# R7FA6M2AF register map
Vendor: Renesas; Series: RA6; File version: 1.2
CPU: CM4 r0p1, little endian, MPU, FPU, VTOR, 4 interrupt priority bits
Registers are 8-bit, read-write, reset 0x0 unless marked. A register's access mark holds for its fields unless they carry their own. Offsets are from the block's base; [hi:lo] are bit positions.

## ETHERC0 — Ethernet Controller Channel 0
Base 0x40064100
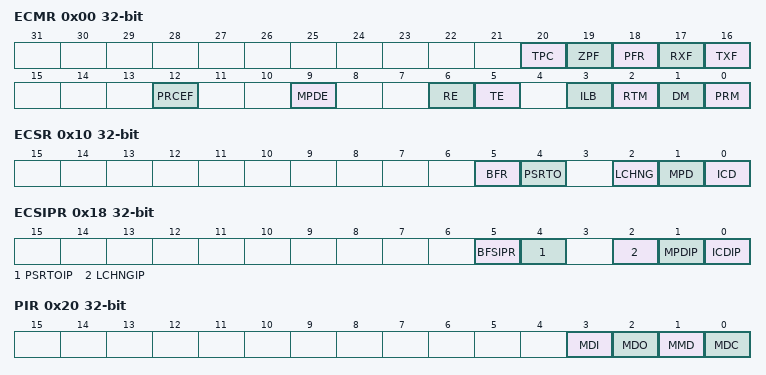
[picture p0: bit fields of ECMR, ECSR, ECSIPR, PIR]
0x00 ECMR 32-bit — ETHERC Mode Register
  [20] TPC — PAUSE Frame Transmit
  [19] ZPF — 0 Time PAUSE Frame Enable
  [18] PFR — PAUSE Frame Receive Mode
  [17] RXF — Receive Flow Control Operating Mode
  [16] TXF — Transmit Flow Control Operating Mode
  [12] PRCEF — CRC Error Frame Receive Mode
  [9] MPDE — Magic Packet Detection Enable
  [6] RE — Reception Enable
  [5] TE — Transmission Enable
  [3] ILB — Internal Loopback Mode
  [2] RTM — Bit Rate
  [1] DM — Duplex Mode
  [0] PRM — Promiscuous Mode
0x08 RFLR 32-bit — Receive Frame Maximum Length Register
  [11:0] RFL — Receive Frame Maximum LengthThe set value becomes the maximum frame length. The minimum value that can be set is 1,518 bytes, and the maximum value that can be set is 2,048 bytes. Values that are less than 1,518 bytes are regarded as 1,518 bytes, and values larger than 2,048 bytes are regarded as 2,048 bytes.
0x10 ECSR 32-bit — ETHERC Status Register
  [5] BFR write-1-clears read-modifies — Continuous Broadcast Frame Reception Flag
  [4] PSRTO write-1-clears read-modifies — PAUSE Frame Retransmit Over Flag
  [2] LCHNG write-1-clears read-modifies — LCHNG Link Signal Change Flag
  [1] MPD write-1-clears read-modifies — Magic Packet Detect Flag
  [0] ICD write-1-clears read-modifies — False Carrier Detect Flag
0x18 ECSIPR 32-bit — ETHERC Interrupt Enable Register
  [5] BFSIPR — Continuous Broadcast Frame Reception Interrupt Enable
  [4] PSRTOIP — PAUSE Frame Retransmit Over Interrupt Enable
  [2] LCHNGIP — LINK Signal Change Interrupt Enable
  [1] MPDIP — Magic Packet Detect Interrupt Enable
  [0] ICDIP — False Carrier Detect Interrupt Enable
0x20 PIR 32-bit (reset mask 0xFFFFFFF7) — PHY Interface Register
  [3] MDI ro — MII/RMII Management Data,InThis bit indicates the level of the ETn_MDIO pin. The write value should be 0.
  [2] MDO — MII/RMII Management Data,OutThe MDO bit value is output from the ETn_MDIO pin when the MMD bit is 1 (write). The value is not output when the MMD bit is 0 (read).
  [1] MMD — MII/RMII Management Mode
  [0] MDC — MII/RMII Management Data ClockThe MDC bit value is output from the ETn_MDC pin to supply the management data clock to the MII or RMII.
0x28 PSR 32-bit ro (reset mask 0xFFFFFFFE) — PHY Status Register
  [0] LMON — ETn_LINKSTA Pin Status FlagThe link status can be read by connecting the link signal output from the PHY,LSI to the ETn_LINKSTA pin. For details on the polarity, refer to the specifications of the connected PHY,LSI.
0x40 RDMLR 32-bit — Random Number Generation Counter Upper Limit Setting Register
  [19:0] RMD — Random Number Generation Counter
0x50 IPGR 32-bit reset 0x14 — IPG Register
  [4:0] IPG — Interpacket Gap Range:"16bit time(0x00)"-"140bit time(0x1F)"
0x54 APR 32-bit — Automatic PAUSE Frame Register
  [15:0] AP — Automatic PAUSE Time SettingThese bits set the value of the pause_time parameter for a PAUSE frame that is automatically transmitted. Transmission is not performed until the set value multiplied by 512 bit time has elapsed.
0x58 MPR 32-bit wo (reset mask 0xFFFF0000) — Manual PAUSE Frame Register
  [15:0] MP — Manual PAUSE Time SettingThese bits set the value of the pause_time parameter for a PAUSE frame that is manually transmitted. Transmission is not performed until the set value multiplied by 512 bit time has elapsed. The read value is undefined.
0x60 RFCF 32-bit ro — Received PAUSE Frame Counter
  [7:0] RPAUSE — Received PAUSE Frame CountNumber of received PAUSE frames
0x64 TPAUSER 32-bit — PAUSE Frame Retransmit Count Setting Register
  [15:0] TPAUSE — Automatic PAUSE Frame Retransmit Setting
0x68 TPAUSECR 32-bit ro — PAUSE Frame Retransmit Counter
0x6C BCFRR 32-bit — Broadcast Frame Receive Count Setting Register
  [15:0] BCF — Broadcast Frame Continuous Receive Count Setting
0xC0 MAHR 32-bit — MAC Address Upper Bit Register
  [31:0] MAHR — MAC Address Upper Bit RegisterThe MAHR register sets the upper 32 bits (b47 to b16) of the 48-bit MAC address.
0xC8 MALR 32-bit — MAC Address Lower Bit Register
  [15:0] MALR — MAC Address Lower Bit RegisterThe MALR register sets the lower 16 bits of the 48-bit MAC address.
0xD0 TROCR 32-bit — Transmit Retry Over Counter Register
  [31:0] TROCR write-clears — Transmit Retry Over Counter RegisterThe TROCR register is a counter indicating the number of frames that fail to be retransmitted.
0xD4 CDCR 32-bit — Late Collision Detect Counter Register
0xD8 LCCR 32-bit — Lost Carrier Counter Register
  [31:0] LCCR write-clears — Lost Carrier Counter RegisterThe LCCR register is a counter indicating the number of times a loss of carrier is detected during frame transmission.
0xDC CNDCR 32-bit — Carrier Not Detect Counter Register
  [31:0] CNDCR write-clears — Carrier Not Detect Counter RegisterThe CNDCR register is a counter indicating the number of times a carrier is not detected during preamble transmission.
0xE4 CEFCR 32-bit — CRC Error Frame Receive Counter Register
  [31:0] CEFCR write-clears — CRC Error Frame Receive Counter RegisterThe CEFCR register is a counter indicating the number of received frames where a CRC error has been detected.
0xE8 FRECR 32-bit — Frame Receive Error Counter Register
  [31:0] FRECR write-clears — Frame Receive Error Counter RegisterThe FRECR register is a counter indicating the number of times a frame receive error has occurred.
0xEC TSFRCR 32-bit — Too,Short Frame Receive Counter Register
  [31:0] TSFRCR write-clears — Too,Short Frame Receive Counter RegisterThe TSFRCR register is a counter indicating the number of times a short frame that is shorter than 64 bytes has been received.
0xF0 TLFRCR 32-bit — Too,Long Frame Receive Counter Register
  [31:0] TLFRCR write-clears — Too,Long Frame Receive Counter RegisterThe TLFRCR register is a counter indicating the number of times a long frame that is longer than the RFLR register value has been received.
0xF4 RFCR 32-bit — Received Alignment Error Frame Counter Register
  [31:0] RFCR write-clears — Received Alignment Error Frame Counter RegisterThe RFCR register is a counter indicating the number of times a frame has been received with the alignment error (frame is not an integral number of octets).
0xF8 MAFCR 32-bit — Multicast Address Frame Receive Counter Register
  [31:0] MAFCR write-clears — Multicast Address Frame Receive Counter RegisterThe MAFCR register is a counter indicating the number of times a frame where the multicast address is set has been received.
